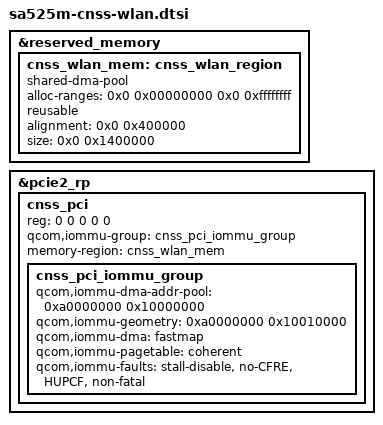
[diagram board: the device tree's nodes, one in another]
// SPDX-License-Identifier: BSD-3-Clause
/*
 * Copyright (c) Qualcomm Technologies, Inc. and/or its subsidiaries.
 */

&reserved_memory {
	cnss_wlan_mem: cnss_wlan_region {
		compatible = "shared-dma-pool";
		alloc-ranges = <0x0 0x00000000 0x0 0xffffffff>;
		reusable;
		alignment = <0x0 0x400000>;
		size = <0x0 0x1400000>;
	};
};

&pcie2_rp {
	#address-cells = <5>;
	#size-cells = <0>;
	cnss_pci: cnss_pci {
		reg = <0 0 0 0 0>;
		qcom,iommu-group = <&cnss_pci_iommu_group>;
		memory-region = <&cnss_wlan_mem>;

		#address-cells = <1>;
		#size-cells = <1>;

		cnss_pci_iommu_group: cnss_pci_iommu_group {
			qcom,iommu-dma-addr-pool = <0xa0000000 0x10000000>;
			qcom,iommu-geometry = <0xa0000000 0x10010000>;
			qcom,iommu-dma = "fastmap";
			qcom,iommu-pagetable = "coherent";
			qcom,iommu-faults = "stall-disable", "no-CFRE", "HUPCF",
					    "non-fatal";
		};
	};
};
